# VPAC0_CP_INTD_CFG_INTD_CFG register map
Vendor: Texas Instruments
Peripheral module from a debugger description file (folder J721S2).
Registers are 32-bit, access not given, reset 0x0 unless marked. A register's access mark holds for its fields unless they carry their own. Offsets are as the file gives them; lines under a group give offsets from that group; [hi:lo] are bit positions; {n}, {i} and the like mark numbered series; 'fields as' and 'values as' point back to an identical list; <NAME> marks a mode.

## VPAC0_CP_INTD_CFG_INTD_CFG (part 1 of 2)
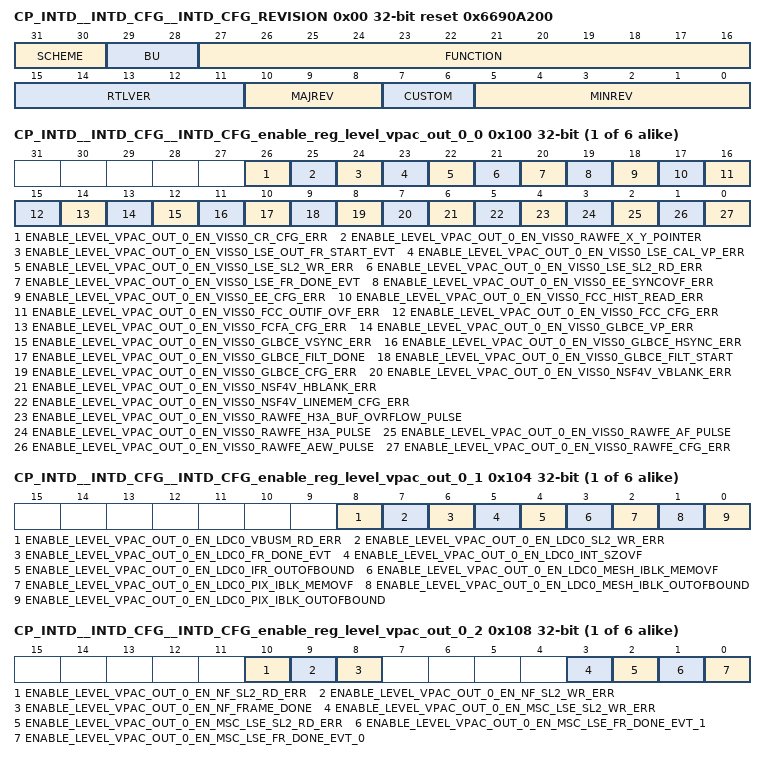
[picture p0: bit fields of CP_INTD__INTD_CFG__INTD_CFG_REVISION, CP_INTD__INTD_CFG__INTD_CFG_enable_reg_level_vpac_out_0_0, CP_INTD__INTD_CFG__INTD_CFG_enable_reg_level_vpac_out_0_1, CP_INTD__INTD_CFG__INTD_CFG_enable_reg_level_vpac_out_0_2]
0x00 CP_INTD__INTD_CFG__INTD_CFG_REVISION ro reset 0x6690A200 — Revision Register
  [31:30] SCHEME
  [29:28] BU
  [27:16] FUNCTION — Module ID
  [15:11] RTLVER — RTL revisions
  [10:8] MAJREV — Major revision
  [7:6] CUSTOM — Custom revision
  [5:0] MINREV — Minor revision
0x10 CP_INTD__INTD_CFG__INTD_CFG_eoi_reg rw — End of Interrupt Register
  [7:0] EOI_VECTOR — End of Interrupt Vector
0x14 CP_INTD__INTD_CFG__INTD_CFG_intr_vector_reg ro — Interrupt Vector Register
  [31:0] INTR_VECTOR
{0x100+0x20*i} CP_INTD__INTD_CFG__INTD_CFG_enable_reg_level_vpac_out_{i}_0 (i=0..5) — Enable Register {8i}
  [26] ENABLE_LEVEL_VPAC_OUT_{i}_EN_VISS0_CR_CFG_ERR — Enable Set for level_vpac_out_{i}_en_viss0_cr_cfg_err (access R/W1TS)
  [25] ENABLE_LEVEL_VPAC_OUT_{i}_EN_VISS0_RAWFE_X_Y_POINTER — Enable Set for level_vpac_out_{i}_en_viss0_rawfe_x_y_pointer (access R/W1TS)
  [24] ENABLE_LEVEL_VPAC_OUT_{i}_EN_VISS0_LSE_OUT_FR_START_EVT — Enable Set for level_vpac_out_{i}_en_viss0_lse_out_fr_start_evt (access R/W1TS)
  [23] ENABLE_LEVEL_VPAC_OUT_{i}_EN_VISS0_LSE_CAL_VP_ERR — Enable Set for level_vpac_out_{i}_en_viss0_lse_cal_vp_err (access R/W1TS)
  [22] ENABLE_LEVEL_VPAC_OUT_{i}_EN_VISS0_LSE_SL2_WR_ERR — Enable Set for level_vpac_out_{i}_en_viss0_lse_sl2_wr_err (access R/W1TS)
  [21] ENABLE_LEVEL_VPAC_OUT_{i}_EN_VISS0_LSE_SL2_RD_ERR — Enable Set for level_vpac_out_{i}_en_viss0_lse_sl2_rd_err (access R/W1TS)
  [20] ENABLE_LEVEL_VPAC_OUT_{i}_EN_VISS0_LSE_FR_DONE_EVT — Enable Set for level_vpac_out_{i}_en_viss0_lse_fr_done_evt (access R/W1TS)
  [19] ENABLE_LEVEL_VPAC_OUT_{i}_EN_VISS0_EE_SYNCOVF_ERR — Enable Set for level_vpac_out_{i}_en_viss0_ee_syncovf_err (access R/W1TS)
  [18] ENABLE_LEVEL_VPAC_OUT_{i}_EN_VISS0_EE_CFG_ERR — Enable Set for level_vpac_out_{i}_en_viss0_ee_cfg_err (access R/W1TS)
  [17] ENABLE_LEVEL_VPAC_OUT_{i}_EN_VISS0_FCC_HIST_READ_ERR — Enable Set for level_vpac_out_{i}_en_viss0_fcc_hist_read_err (access R/W1TS)
  [16] ENABLE_LEVEL_VPAC_OUT_{i}_EN_VISS0_FCC_OUTIF_OVF_ERR — Enable Set for level_vpac_out_{i}_en_viss0_fcc_outif_ovf_err (access R/W1TS)
  [15] ENABLE_LEVEL_VPAC_OUT_{i}_EN_VISS0_FCC_CFG_ERR — Enable Set for level_vpac_out_{i}_en_viss0_fcc_cfg_err (access R/W1TS)
  [14] ENABLE_LEVEL_VPAC_OUT_{i}_EN_VISS0_FCFA_CFG_ERR — Enable Set for level_vpac_out_{i}_en_viss0_fcfa_cfg_err (access R/W1TS)
  [13] ENABLE_LEVEL_VPAC_OUT_{i}_EN_VISS0_GLBCE_VP_ERR — Enable Set for level_vpac_out_{i}_en_viss0_glbce_vp_err (access R/W1TS)
  [12] ENABLE_LEVEL_VPAC_OUT_{i}_EN_VISS0_GLBCE_VSYNC_ERR — Enable Set for level_vpac_out_{i}_en_viss0_glbce_vsync_err (access R/W1TS)
  [11] ENABLE_LEVEL_VPAC_OUT_{i}_EN_VISS0_GLBCE_HSYNC_ERR — Enable Set for level_vpac_out_{i}_en_viss0_glbce_hsync_err (access R/W1TS)
  [10] ENABLE_LEVEL_VPAC_OUT_{i}_EN_VISS0_GLBCE_FILT_DONE — Enable Set for level_vpac_out_{i}_en_viss0_glbce_filt_done (access R/W1TS)
  [9] ENABLE_LEVEL_VPAC_OUT_{i}_EN_VISS0_GLBCE_FILT_START — Enable Set for level_vpac_out_{i}_en_viss0_glbce_filt_start (access R/W1TS)
  [8] ENABLE_LEVEL_VPAC_OUT_{i}_EN_VISS0_GLBCE_CFG_ERR — Enable Set for level_vpac_out_{i}_en_viss0_glbce_cfg_err (access R/W1TS)
  [7] ENABLE_LEVEL_VPAC_OUT_{i}_EN_VISS0_NSF4V_VBLANK_ERR — Enable Set for level_vpac_out_{i}_en_viss0_nsf4v_vblank_err (access R/W1TS)
  [6] ENABLE_LEVEL_VPAC_OUT_{i}_EN_VISS0_NSF4V_HBLANK_ERR — Enable Set for level_vpac_out_{i}_en_viss0_nsf4v_hblank_err (access R/W1TS)
  [5] ENABLE_LEVEL_VPAC_OUT_{i}_EN_VISS0_NSF4V_LINEMEM_CFG_ERR — Enable Set for level_vpac_out_{i}_en_viss0_nsf4v_linemem_cfg_err (access R/W1TS)
  [4] ENABLE_LEVEL_VPAC_OUT_{i}_EN_VISS0_RAWFE_H3A_BUF_OVRFLOW_PULSE — Enable Set for level_vpac_out_{i}_en_viss0_rawfe_h3a_buf_ovrflow_pulse (access R/W1TS)
  [3] ENABLE_LEVEL_VPAC_OUT_{i}_EN_VISS0_RAWFE_H3A_PULSE — Enable Set for level_vpac_out_{i}_en_viss0_rawfe_h3a_pulse (access R/W1TS)
  [2] ENABLE_LEVEL_VPAC_OUT_{i}_EN_VISS0_RAWFE_AF_PULSE — Enable Set for level_vpac_out_{i}_en_viss0_rawfe_af_pulse (access R/W1TS)
  [1] ENABLE_LEVEL_VPAC_OUT_{i}_EN_VISS0_RAWFE_AEW_PULSE — Enable Set for level_vpac_out_{i}_en_viss0_rawfe_aew_pulse (access R/W1TS)
  [0] ENABLE_LEVEL_VPAC_OUT_{i}_EN_VISS0_RAWFE_CFG_ERR — Enable Set for level_vpac_out_{i}_en_viss0_rawfe_cfg_err (access R/W1TS)
{0x104+0x20*i} CP_INTD__INTD_CFG__INTD_CFG_enable_reg_level_vpac_out_{i}_1 (i=0..5) — Enable Register {8i+1}
  [8] ENABLE_LEVEL_VPAC_OUT_{i}_EN_LDC0_VBUSM_RD_ERR — Enable Set for level_vpac_out_{i}_en_ldc0_vbusm_rd_err (access R/W1TS)
  [7] ENABLE_LEVEL_VPAC_OUT_{i}_EN_LDC0_SL2_WR_ERR — Enable Set for level_vpac_out_{i}_en_ldc0_sl2_wr_err (access R/W1TS)
  [6] ENABLE_LEVEL_VPAC_OUT_{i}_EN_LDC0_FR_DONE_EVT — Enable Set for level_vpac_out_{i}_en_ldc0_fr_done_evt (access R/W1TS)
  [5] ENABLE_LEVEL_VPAC_OUT_{i}_EN_LDC0_INT_SZOVF — Enable Set for level_vpac_out_{i}_en_ldc0_int_szovf (access R/W1TS)
  [4] ENABLE_LEVEL_VPAC_OUT_{i}_EN_LDC0_IFR_OUTOFBOUND — Enable Set for level_vpac_out_{i}_en_ldc0_ifr_outofbound (access R/W1TS)
  [3] ENABLE_LEVEL_VPAC_OUT_{i}_EN_LDC0_MESH_IBLK_MEMOVF — Enable Set for level_vpac_out_{i}_en_ldc0_mesh_iblk_memovf (access R/W1TS)
  [2] ENABLE_LEVEL_VPAC_OUT_{i}_EN_LDC0_PIX_IBLK_MEMOVF — Enable Set for level_vpac_out_{i}_en_ldc0_pix_iblk_memovf (access R/W1TS)
  [1] ENABLE_LEVEL_VPAC_OUT_{i}_EN_LDC0_MESH_IBLK_OUTOFBOUND — Enable Set for level_vpac_out_{i}_en_ldc0_mesh_iblk_outofbound (access R/W1TS)
  [0] ENABLE_LEVEL_VPAC_OUT_{i}_EN_LDC0_PIX_IBLK_OUTOFBOUND — Enable Set for level_vpac_out_{i}_en_ldc0_pix_iblk_outofbound (access R/W1TS)
{0x108+0x20*i} CP_INTD__INTD_CFG__INTD_CFG_enable_reg_level_vpac_out_{i}_2 (i=0..5) — Enable Register {8i+2}
  [10] ENABLE_LEVEL_VPAC_OUT_{i}_EN_NF_SL2_RD_ERR — Enable Set for level_vpac_out_{i}_en_nf_sl2_rd_err (access R/W1TS)
  [9] ENABLE_LEVEL_VPAC_OUT_{i}_EN_NF_SL2_WR_ERR — Enable Set for level_vpac_out_{i}_en_nf_sl2_wr_err (access R/W1TS)
  [8] ENABLE_LEVEL_VPAC_OUT_{i}_EN_NF_FRAME_DONE — Enable Set for level_vpac_out_{i}_en_nf_frame_done (access R/W1TS)
  [3] ENABLE_LEVEL_VPAC_OUT_{i}_EN_MSC_LSE_SL2_WR_ERR — Enable Set for level_vpac_out_{i}_en_msc_lse_sl2_wr_err (access R/W1TS)
  [2] ENABLE_LEVEL_VPAC_OUT_{i}_EN_MSC_LSE_SL2_RD_ERR — Enable Set for level_vpac_out_{i}_en_msc_lse_sl2_rd_err (access R/W1TS)
  [1] ENABLE_LEVEL_VPAC_OUT_{i}_EN_MSC_LSE_FR_DONE_EVT_1 — Enable Set for level_vpac_out_{i}_en_msc_lse_fr_done_evt_1 (access R/W1TS)
  [0] ENABLE_LEVEL_VPAC_OUT_{i}_EN_MSC_LSE_FR_DONE_EVT_0 — Enable Set for level_vpac_out_{i}_en_msc_lse_fr_done_evt_0 (access R/W1TS)
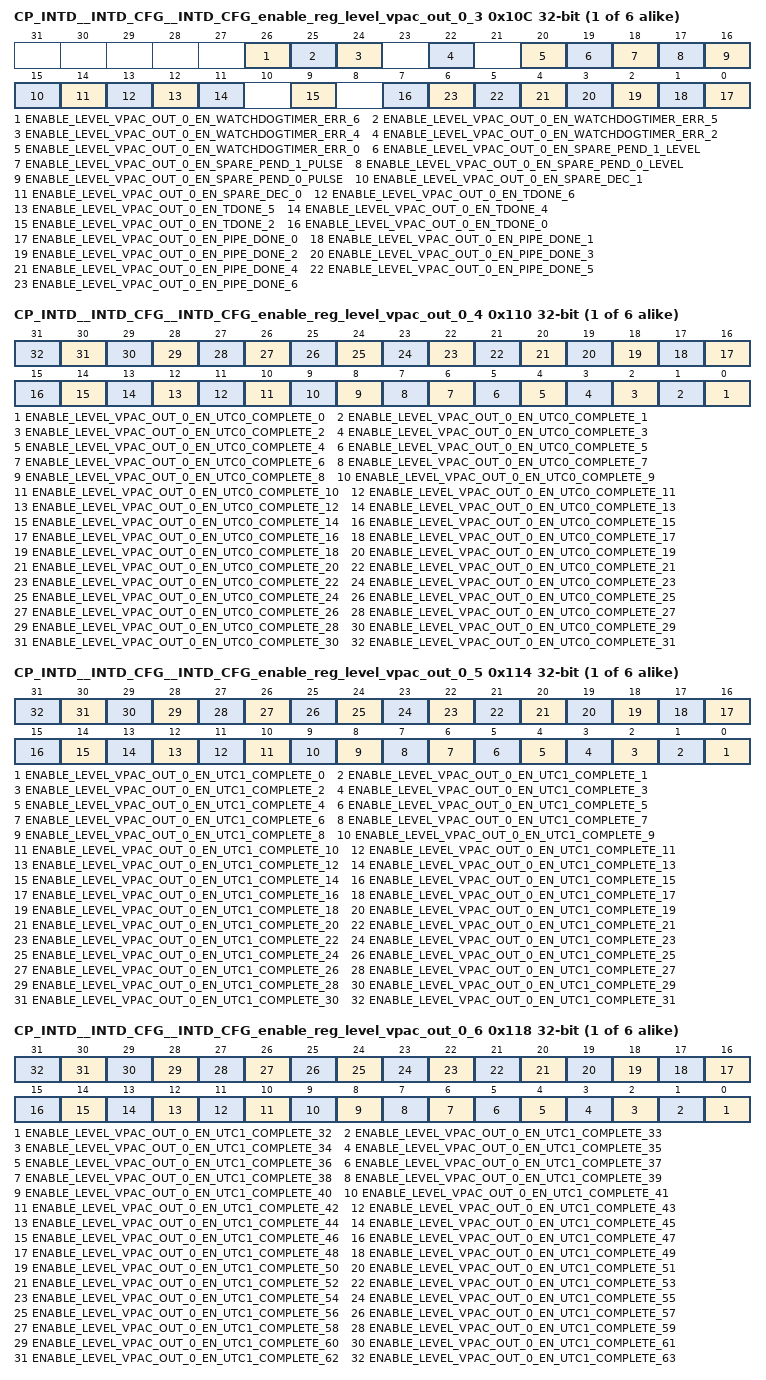
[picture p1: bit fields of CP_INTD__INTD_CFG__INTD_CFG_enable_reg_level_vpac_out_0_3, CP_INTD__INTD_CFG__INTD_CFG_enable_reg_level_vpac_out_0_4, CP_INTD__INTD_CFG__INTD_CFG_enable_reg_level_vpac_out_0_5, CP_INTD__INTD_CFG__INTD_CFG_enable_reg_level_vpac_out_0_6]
{0x10C+0x20*i} CP_INTD__INTD_CFG__INTD_CFG_enable_reg_level_vpac_out_{i}_3 (i=0..5) — Enable Register {8i+3}
  [26] ENABLE_LEVEL_VPAC_OUT_{i}_EN_WATCHDOGTIMER_ERR_6 — Enable Set for level_vpac_out_{i}_en_watchdogtimer_err_6 (access R/W1TS)
  [25] ENABLE_LEVEL_VPAC_OUT_{i}_EN_WATCHDOGTIMER_ERR_5 — Enable Set for level_vpac_out_{i}_en_watchdogtimer_err_5 (access R/W1TS)
  [24] ENABLE_LEVEL_VPAC_OUT_{i}_EN_WATCHDOGTIMER_ERR_4 — Enable Set for level_vpac_out_{i}_en_watchdogtimer_err_4 (access R/W1TS)
  [22] ENABLE_LEVEL_VPAC_OUT_{i}_EN_WATCHDOGTIMER_ERR_2 — Enable Set for level_vpac_out_{i}_en_watchdogtimer_err_2 (access R/W1TS)
  [20] ENABLE_LEVEL_VPAC_OUT_{i}_EN_WATCHDOGTIMER_ERR_0 — Enable Set for level_vpac_out_{i}_en_watchdogtimer_err_0 (access R/W1TS)
  [19] ENABLE_LEVEL_VPAC_OUT_{i}_EN_SPARE_PEND_1_LEVEL — Enable Set for level_vpac_out_{i}_en_spare_pend_1_level (access R/W1TS)
  [18] ENABLE_LEVEL_VPAC_OUT_{i}_EN_SPARE_PEND_1_PULSE — Enable Set for level_vpac_out_{i}_en_spare_pend_1_pulse (access R/W1TS)
  [17] ENABLE_LEVEL_VPAC_OUT_{i}_EN_SPARE_PEND_0_LEVEL — Enable Set for level_vpac_out_{i}_en_spare_pend_0_level (access R/W1TS)
  [16] ENABLE_LEVEL_VPAC_OUT_{i}_EN_SPARE_PEND_0_PULSE — Enable Set for level_vpac_out_{i}_en_spare_pend_0_pulse (access R/W1TS)
  [15] ENABLE_LEVEL_VPAC_OUT_{i}_EN_SPARE_DEC_1 — Enable Set for level_vpac_out_{i}_en_spare_dec_1 (access R/W1TS)
  [14] ENABLE_LEVEL_VPAC_OUT_{i}_EN_SPARE_DEC_0 — Enable Set for level_vpac_out_{i}_en_spare_dec_0 (access R/W1TS)
  [13] ENABLE_LEVEL_VPAC_OUT_{i}_EN_TDONE_6 — Enable Set for level_vpac_out_{i}_en_tdone_6 (access R/W1TS)
  [12] ENABLE_LEVEL_VPAC_OUT_{i}_EN_TDONE_5 — Enable Set for level_vpac_out_{i}_en_tdone_5 (access R/W1TS)
  [11] ENABLE_LEVEL_VPAC_OUT_{i}_EN_TDONE_4 — Enable Set for level_vpac_out_{i}_en_tdone_4 (access R/W1TS)
  [9] ENABLE_LEVEL_VPAC_OUT_{i}_EN_TDONE_2 — Enable Set for level_vpac_out_{i}_en_tdone_2 (access R/W1TS)
  [7] ENABLE_LEVEL_VPAC_OUT_{i}_EN_TDONE_0 — Enable Set for level_vpac_out_{i}_en_tdone_0 (access R/W1TS)
  [n] ENABLE_LEVEL_VPAC_OUT_{i}_EN_PIPE_DONE_{n} (n=0..6) — Enable Set for level_vpac_out_{i}_en_pipe_done_{n} (access R/W1TS)
{0x110+0x20*i} CP_INTD__INTD_CFG__INTD_CFG_enable_reg_level_vpac_out_{i}_4 (i=0..5) — Enable Register {8i+4}
  [n] ENABLE_LEVEL_VPAC_OUT_{i}_EN_UTC0_COMPLETE_{n} (n=0..31) — Enable Set for level_vpac_out_{i}_en_utc0_complete_{n} (access R/W1TS)
{0x114+0x20*i} CP_INTD__INTD_CFG__INTD_CFG_enable_reg_level_vpac_out_{i}_5 (i=0..5) — Enable Register {8i+5}
  [n] ENABLE_LEVEL_VPAC_OUT_{i}_EN_UTC1_COMPLETE_{n} (n=0..31) — Enable Set for level_vpac_out_{i}_en_utc1_complete_{n} (access R/W1TS)
{0x118+0x20*i} CP_INTD__INTD_CFG__INTD_CFG_enable_reg_level_vpac_out_{i}_6 (i=0..5) — Enable Register {8i+6}
  [n-32] ENABLE_LEVEL_VPAC_OUT_{i}_EN_UTC1_COMPLETE_{n} (n=32..63) — Enable Set for level_vpac_out_{i}_en_utc1_complete_{n} (access R/W1TS)
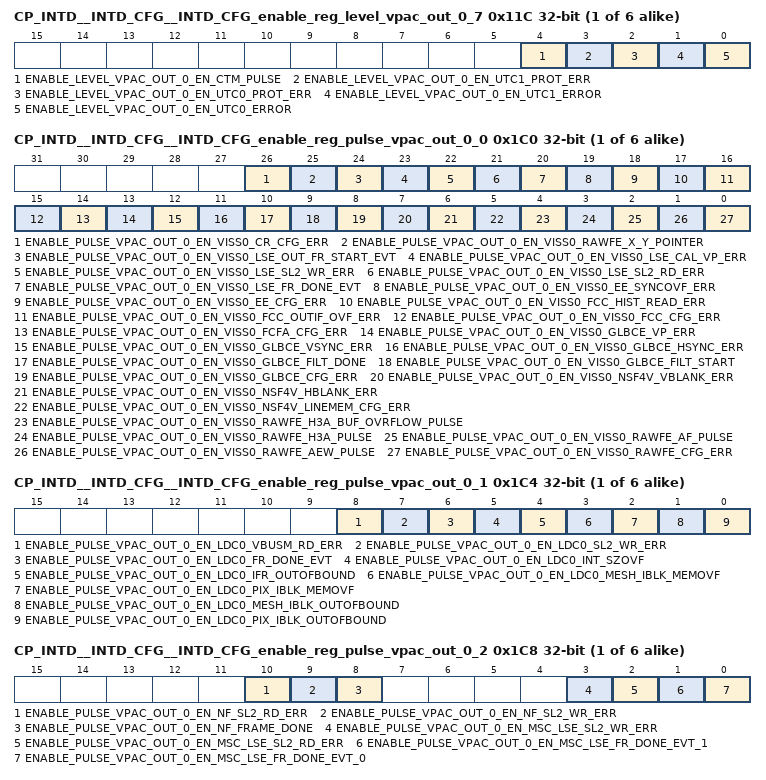
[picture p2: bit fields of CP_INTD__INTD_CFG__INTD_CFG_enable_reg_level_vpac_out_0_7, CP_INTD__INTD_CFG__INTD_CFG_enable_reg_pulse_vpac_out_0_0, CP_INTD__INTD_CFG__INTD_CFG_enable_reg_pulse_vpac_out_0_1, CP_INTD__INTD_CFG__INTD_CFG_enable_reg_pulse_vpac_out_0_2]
{0x11C+0x20*i} CP_INTD__INTD_CFG__INTD_CFG_enable_reg_level_vpac_out_{i}_7 (i=0..5) — Enable Register {8i+7}
  [4] ENABLE_LEVEL_VPAC_OUT_{i}_EN_CTM_PULSE — Enable Set for level_vpac_out_{i}_en_ctm_pulse (access R/W1TS)
  [3] ENABLE_LEVEL_VPAC_OUT_{i}_EN_UTC1_PROT_ERR — Enable Set for level_vpac_out_{i}_en_utc1_prot_err (access R/W1TS)
  [2] ENABLE_LEVEL_VPAC_OUT_{i}_EN_UTC0_PROT_ERR — Enable Set for level_vpac_out_{i}_en_utc0_prot_err (access R/W1TS)
  [1] ENABLE_LEVEL_VPAC_OUT_{i}_EN_UTC1_ERROR — Enable Set for level_vpac_out_{i}_en_utc1_error (access R/W1TS)
  [0] ENABLE_LEVEL_VPAC_OUT_{i}_EN_UTC0_ERROR — Enable Set for level_vpac_out_{i}_en_utc0_error (access R/W1TS)
{0x1C0+0x20*i} CP_INTD__INTD_CFG__INTD_CFG_enable_reg_pulse_vpac_out_{i}_0 (i=0..5) — Enable Register {8i+48}
  [26] ENABLE_PULSE_VPAC_OUT_{i}_EN_VISS0_CR_CFG_ERR — Enable Set for pulse_vpac_out_{i}_en_viss0_cr_cfg_err (access R/W1TS)
  [25] ENABLE_PULSE_VPAC_OUT_{i}_EN_VISS0_RAWFE_X_Y_POINTER — Enable Set for pulse_vpac_out_{i}_en_viss0_rawfe_x_y_pointer (access R/W1TS)
  [24] ENABLE_PULSE_VPAC_OUT_{i}_EN_VISS0_LSE_OUT_FR_START_EVT — Enable Set for pulse_vpac_out_{i}_en_viss0_lse_out_fr_start_evt (access R/W1TS)
  [23] ENABLE_PULSE_VPAC_OUT_{i}_EN_VISS0_LSE_CAL_VP_ERR — Enable Set for pulse_vpac_out_{i}_en_viss0_lse_cal_vp_err (access R/W1TS)
  [22] ENABLE_PULSE_VPAC_OUT_{i}_EN_VISS0_LSE_SL2_WR_ERR — Enable Set for pulse_vpac_out_{i}_en_viss0_lse_sl2_wr_err (access R/W1TS)
  [21] ENABLE_PULSE_VPAC_OUT_{i}_EN_VISS0_LSE_SL2_RD_ERR — Enable Set for pulse_vpac_out_{i}_en_viss0_lse_sl2_rd_err (access R/W1TS)
  [20] ENABLE_PULSE_VPAC_OUT_{i}_EN_VISS0_LSE_FR_DONE_EVT — Enable Set for pulse_vpac_out_{i}_en_viss0_lse_fr_done_evt (access R/W1TS)
  [19] ENABLE_PULSE_VPAC_OUT_{i}_EN_VISS0_EE_SYNCOVF_ERR — Enable Set for pulse_vpac_out_{i}_en_viss0_ee_syncovf_err (access R/W1TS)
  [18] ENABLE_PULSE_VPAC_OUT_{i}_EN_VISS0_EE_CFG_ERR — Enable Set for pulse_vpac_out_{i}_en_viss0_ee_cfg_err (access R/W1TS)
  [17] ENABLE_PULSE_VPAC_OUT_{i}_EN_VISS0_FCC_HIST_READ_ERR — Enable Set for pulse_vpac_out_{i}_en_viss0_fcc_hist_read_err (access R/W1TS)
  [16] ENABLE_PULSE_VPAC_OUT_{i}_EN_VISS0_FCC_OUTIF_OVF_ERR — Enable Set for pulse_vpac_out_{i}_en_viss0_fcc_outif_ovf_err (access R/W1TS)
  [15] ENABLE_PULSE_VPAC_OUT_{i}_EN_VISS0_FCC_CFG_ERR — Enable Set for pulse_vpac_out_{i}_en_viss0_fcc_cfg_err (access R/W1TS)
  [14] ENABLE_PULSE_VPAC_OUT_{i}_EN_VISS0_FCFA_CFG_ERR — Enable Set for pulse_vpac_out_{i}_en_viss0_fcfa_cfg_err (access R/W1TS)
  [13] ENABLE_PULSE_VPAC_OUT_{i}_EN_VISS0_GLBCE_VP_ERR — Enable Set for pulse_vpac_out_{i}_en_viss0_glbce_vp_err (access R/W1TS)
  [12] ENABLE_PULSE_VPAC_OUT_{i}_EN_VISS0_GLBCE_VSYNC_ERR — Enable Set for pulse_vpac_out_{i}_en_viss0_glbce_vsync_err (access R/W1TS)
  [11] ENABLE_PULSE_VPAC_OUT_{i}_EN_VISS0_GLBCE_HSYNC_ERR — Enable Set for pulse_vpac_out_{i}_en_viss0_glbce_hsync_err (access R/W1TS)
  [10] ENABLE_PULSE_VPAC_OUT_{i}_EN_VISS0_GLBCE_FILT_DONE — Enable Set for pulse_vpac_out_{i}_en_viss0_glbce_filt_done (access R/W1TS)
  [9] ENABLE_PULSE_VPAC_OUT_{i}_EN_VISS0_GLBCE_FILT_START — Enable Set for pulse_vpac_out_{i}_en_viss0_glbce_filt_start (access R/W1TS)
  [8] ENABLE_PULSE_VPAC_OUT_{i}_EN_VISS0_GLBCE_CFG_ERR — Enable Set for pulse_vpac_out_{i}_en_viss0_glbce_cfg_err (access R/W1TS)
  [7] ENABLE_PULSE_VPAC_OUT_{i}_EN_VISS0_NSF4V_VBLANK_ERR — Enable Set for pulse_vpac_out_{i}_en_viss0_nsf4v_vblank_err (access R/W1TS)
  [6] ENABLE_PULSE_VPAC_OUT_{i}_EN_VISS0_NSF4V_HBLANK_ERR — Enable Set for pulse_vpac_out_{i}_en_viss0_nsf4v_hblank_err (access R/W1TS)
  [5] ENABLE_PULSE_VPAC_OUT_{i}_EN_VISS0_NSF4V_LINEMEM_CFG_ERR — Enable Set for pulse_vpac_out_{i}_en_viss0_nsf4v_linemem_cfg_err (access R/W1TS)
  [4] ENABLE_PULSE_VPAC_OUT_{i}_EN_VISS0_RAWFE_H3A_BUF_OVRFLOW_PULSE — Enable Set for pulse_vpac_out_{i}_en_viss0_rawfe_h3a_buf_ovrflow_pulse (access R/W1TS)
  [3] ENABLE_PULSE_VPAC_OUT_{i}_EN_VISS0_RAWFE_H3A_PULSE — Enable Set for pulse_vpac_out_{i}_en_viss0_rawfe_h3a_pulse (access R/W1TS)
  [2] ENABLE_PULSE_VPAC_OUT_{i}_EN_VISS0_RAWFE_AF_PULSE — Enable Set for pulse_vpac_out_{i}_en_viss0_rawfe_af_pulse (access R/W1TS)
  [1] ENABLE_PULSE_VPAC_OUT_{i}_EN_VISS0_RAWFE_AEW_PULSE — Enable Set for pulse_vpac_out_{i}_en_viss0_rawfe_aew_pulse (access R/W1TS)
  [0] ENABLE_PULSE_VPAC_OUT_{i}_EN_VISS0_RAWFE_CFG_ERR — Enable Set for pulse_vpac_out_{i}_en_viss0_rawfe_cfg_err (access R/W1TS)
{0x1C4+0x20*i} CP_INTD__INTD_CFG__INTD_CFG_enable_reg_pulse_vpac_out_{i}_1 (i=0..5) — Enable Register {8i+49}
  [8] ENABLE_PULSE_VPAC_OUT_{i}_EN_LDC0_VBUSM_RD_ERR — Enable Set for pulse_vpac_out_{i}_en_ldc0_vbusm_rd_err (access R/W1TS)
  [7] ENABLE_PULSE_VPAC_OUT_{i}_EN_LDC0_SL2_WR_ERR — Enable Set for pulse_vpac_out_{i}_en_ldc0_sl2_wr_err (access R/W1TS)
  [6] ENABLE_PULSE_VPAC_OUT_{i}_EN_LDC0_FR_DONE_EVT — Enable Set for pulse_vpac_out_{i}_en_ldc0_fr_done_evt (access R/W1TS)
  [5] ENABLE_PULSE_VPAC_OUT_{i}_EN_LDC0_INT_SZOVF — Enable Set for pulse_vpac_out_{i}_en_ldc0_int_szovf (access R/W1TS)
  [4] ENABLE_PULSE_VPAC_OUT_{i}_EN_LDC0_IFR_OUTOFBOUND — Enable Set for pulse_vpac_out_{i}_en_ldc0_ifr_outofbound (access R/W1TS)
  [3] ENABLE_PULSE_VPAC_OUT_{i}_EN_LDC0_MESH_IBLK_MEMOVF — Enable Set for pulse_vpac_out_{i}_en_ldc0_mesh_iblk_memovf (access R/W1TS)
  [2] ENABLE_PULSE_VPAC_OUT_{i}_EN_LDC0_PIX_IBLK_MEMOVF — Enable Set for pulse_vpac_out_{i}_en_ldc0_pix_iblk_memovf (access R/W1TS)
  [1] ENABLE_PULSE_VPAC_OUT_{i}_EN_LDC0_MESH_IBLK_OUTOFBOUND — Enable Set for pulse_vpac_out_{i}_en_ldc0_mesh_iblk_outofbound (access R/W1TS)
  [0] ENABLE_PULSE_VPAC_OUT_{i}_EN_LDC0_PIX_IBLK_OUTOFBOUND — Enable Set for pulse_vpac_out_{i}_en_ldc0_pix_iblk_outofbound (access R/W1TS)
{0x1C8+0x20*i} CP_INTD__INTD_CFG__INTD_CFG_enable_reg_pulse_vpac_out_{i}_2 (i=0..5) — Enable Register {8i+50}
  [10] ENABLE_PULSE_VPAC_OUT_{i}_EN_NF_SL2_RD_ERR — Enable Set for pulse_vpac_out_{i}_en_nf_sl2_rd_err (access R/W1TS)
  [9] ENABLE_PULSE_VPAC_OUT_{i}_EN_NF_SL2_WR_ERR — Enable Set for pulse_vpac_out_{i}_en_nf_sl2_wr_err (access R/W1TS)
  [8] ENABLE_PULSE_VPAC_OUT_{i}_EN_NF_FRAME_DONE — Enable Set for pulse_vpac_out_{i}_en_nf_frame_done (access R/W1TS)
  [3] ENABLE_PULSE_VPAC_OUT_{i}_EN_MSC_LSE_SL2_WR_ERR — Enable Set for pulse_vpac_out_{i}_en_msc_lse_sl2_wr_err (access R/W1TS)
  [2] ENABLE_PULSE_VPAC_OUT_{i}_EN_MSC_LSE_SL2_RD_ERR — Enable Set for pulse_vpac_out_{i}_en_msc_lse_sl2_rd_err (access R/W1TS)
  [1] ENABLE_PULSE_VPAC_OUT_{i}_EN_MSC_LSE_FR_DONE_EVT_1 — Enable Set for pulse_vpac_out_{i}_en_msc_lse_fr_done_evt_1 (access R/W1TS)
  [0] ENABLE_PULSE_VPAC_OUT_{i}_EN_MSC_LSE_FR_DONE_EVT_0 — Enable Set for pulse_vpac_out_{i}_en_msc_lse_fr_done_evt_0 (access R/W1TS)
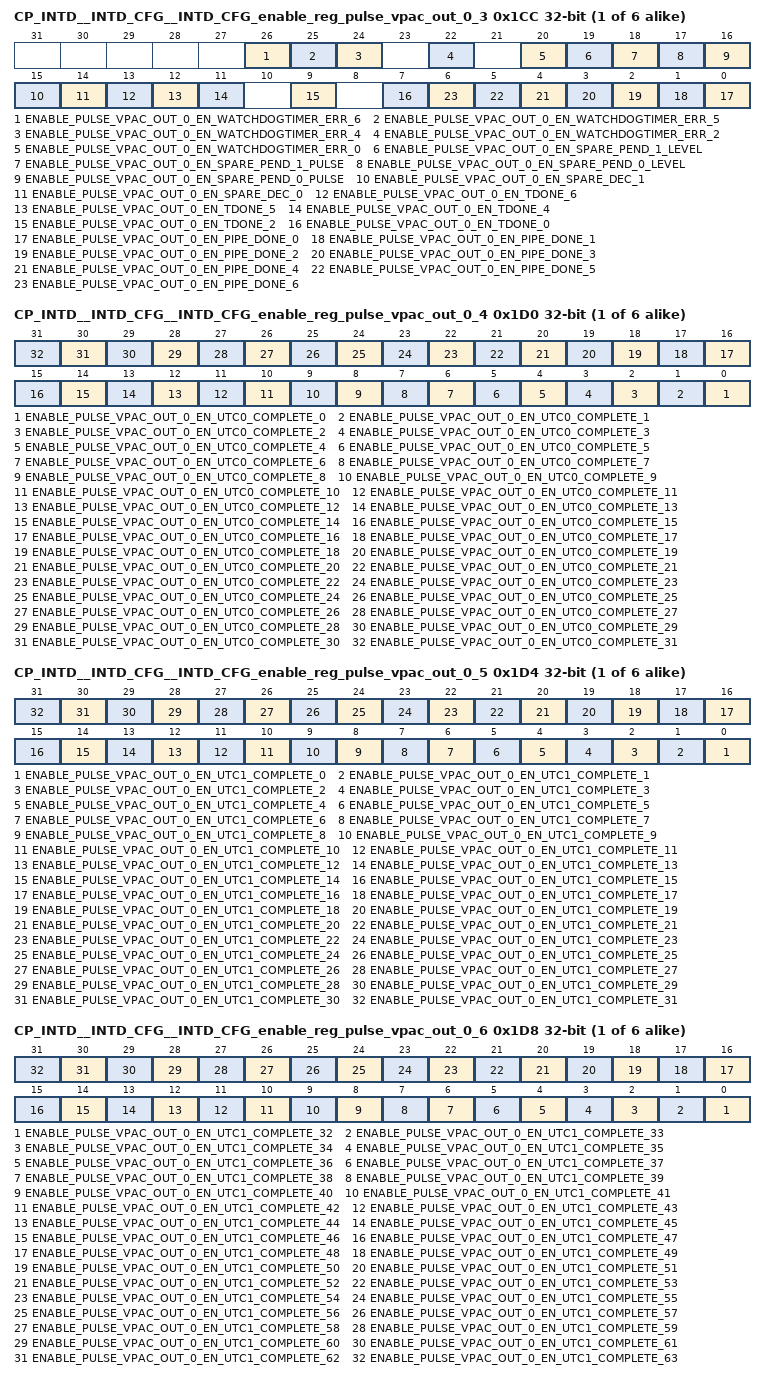
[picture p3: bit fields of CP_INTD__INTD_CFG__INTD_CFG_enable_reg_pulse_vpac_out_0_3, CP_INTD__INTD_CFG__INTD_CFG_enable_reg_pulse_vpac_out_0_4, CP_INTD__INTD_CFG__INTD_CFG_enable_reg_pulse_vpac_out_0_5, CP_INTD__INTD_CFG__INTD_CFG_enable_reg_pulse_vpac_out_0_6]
{0x1CC+0x20*i} CP_INTD__INTD_CFG__INTD_CFG_enable_reg_pulse_vpac_out_{i}_3 (i=0..5) — Enable Register {8i+51}
  [26] ENABLE_PULSE_VPAC_OUT_{i}_EN_WATCHDOGTIMER_ERR_6 — Enable Set for pulse_vpac_out_{i}_en_watchdogtimer_err_6 (access R/W1TS)
  [25] ENABLE_PULSE_VPAC_OUT_{i}_EN_WATCHDOGTIMER_ERR_5 — Enable Set for pulse_vpac_out_{i}_en_watchdogtimer_err_5 (access R/W1TS)
  [24] ENABLE_PULSE_VPAC_OUT_{i}_EN_WATCHDOGTIMER_ERR_4 — Enable Set for pulse_vpac_out_{i}_en_watchdogtimer_err_4 (access R/W1TS)
  [22] ENABLE_PULSE_VPAC_OUT_{i}_EN_WATCHDOGTIMER_ERR_2 — Enable Set for pulse_vpac_out_{i}_en_watchdogtimer_err_2 (access R/W1TS)
  [20] ENABLE_PULSE_VPAC_OUT_{i}_EN_WATCHDOGTIMER_ERR_0 — Enable Set for pulse_vpac_out_{i}_en_watchdogtimer_err_0 (access R/W1TS)
  [19] ENABLE_PULSE_VPAC_OUT_{i}_EN_SPARE_PEND_1_LEVEL — Enable Set for pulse_vpac_out_{i}_en_spare_pend_1_level (access R/W1TS)
  [18] ENABLE_PULSE_VPAC_OUT_{i}_EN_SPARE_PEND_1_PULSE — Enable Set for pulse_vpac_out_{i}_en_spare_pend_1_pulse (access R/W1TS)
  [17] ENABLE_PULSE_VPAC_OUT_{i}_EN_SPARE_PEND_0_LEVEL — Enable Set for pulse_vpac_out_{i}_en_spare_pend_0_level (access R/W1TS)
  [16] ENABLE_PULSE_VPAC_OUT_{i}_EN_SPARE_PEND_0_PULSE — Enable Set for pulse_vpac_out_{i}_en_spare_pend_0_pulse (access R/W1TS)
  [15] ENABLE_PULSE_VPAC_OUT_{i}_EN_SPARE_DEC_1 — Enable Set for pulse_vpac_out_{i}_en_spare_dec_1 (access R/W1TS)
  [14] ENABLE_PULSE_VPAC_OUT_{i}_EN_SPARE_DEC_0 — Enable Set for pulse_vpac_out_{i}_en_spare_dec_0 (access R/W1TS)
  [13] ENABLE_PULSE_VPAC_OUT_{i}_EN_TDONE_6 — Enable Set for pulse_vpac_out_{i}_en_tdone_6 (access R/W1TS)
  [12] ENABLE_PULSE_VPAC_OUT_{i}_EN_TDONE_5 — Enable Set for pulse_vpac_out_{i}_en_tdone_5 (access R/W1TS)
  [11] ENABLE_PULSE_VPAC_OUT_{i}_EN_TDONE_4 — Enable Set for pulse_vpac_out_{i}_en_tdone_4 (access R/W1TS)
  [9] ENABLE_PULSE_VPAC_OUT_{i}_EN_TDONE_2 — Enable Set for pulse_vpac_out_{i}_en_tdone_2 (access R/W1TS)
  [7] ENABLE_PULSE_VPAC_OUT_{i}_EN_TDONE_0 — Enable Set for pulse_vpac_out_{i}_en_tdone_0 (access R/W1TS)
  [n] ENABLE_PULSE_VPAC_OUT_{i}_EN_PIPE_DONE_{n} (n=0..6) — Enable Set for pulse_vpac_out_{i}_en_pipe_done_{n} (access R/W1TS)
{0x1D0+0x20*i} CP_INTD__INTD_CFG__INTD_CFG_enable_reg_pulse_vpac_out_{i}_4 (i=0..5) — Enable Register {8i+52}
  [n] ENABLE_PULSE_VPAC_OUT_{i}_EN_UTC0_COMPLETE_{n} (n=0..31) — Enable Set for pulse_vpac_out_{i}_en_utc0_complete_{n} (access R/W1TS)
{0x1D4+0x20*i} CP_INTD__INTD_CFG__INTD_CFG_enable_reg_pulse_vpac_out_{i}_5 (i=0..5) — Enable Register {8i+53}
  [n] ENABLE_PULSE_VPAC_OUT_{i}_EN_UTC1_COMPLETE_{n} (n=0..31) — Enable Set for pulse_vpac_out_{i}_en_utc1_complete_{n} (access R/W1TS)
{0x1D8+0x20*i} CP_INTD__INTD_CFG__INTD_CFG_enable_reg_pulse_vpac_out_{i}_6 (i=0..5) — Enable Register {8i+54}
  [n-32] ENABLE_PULSE_VPAC_OUT_{i}_EN_UTC1_COMPLETE_{n} (n=32..63) — Enable Set for pulse_vpac_out_{i}_en_utc1_complete_{n} (access R/W1TS)
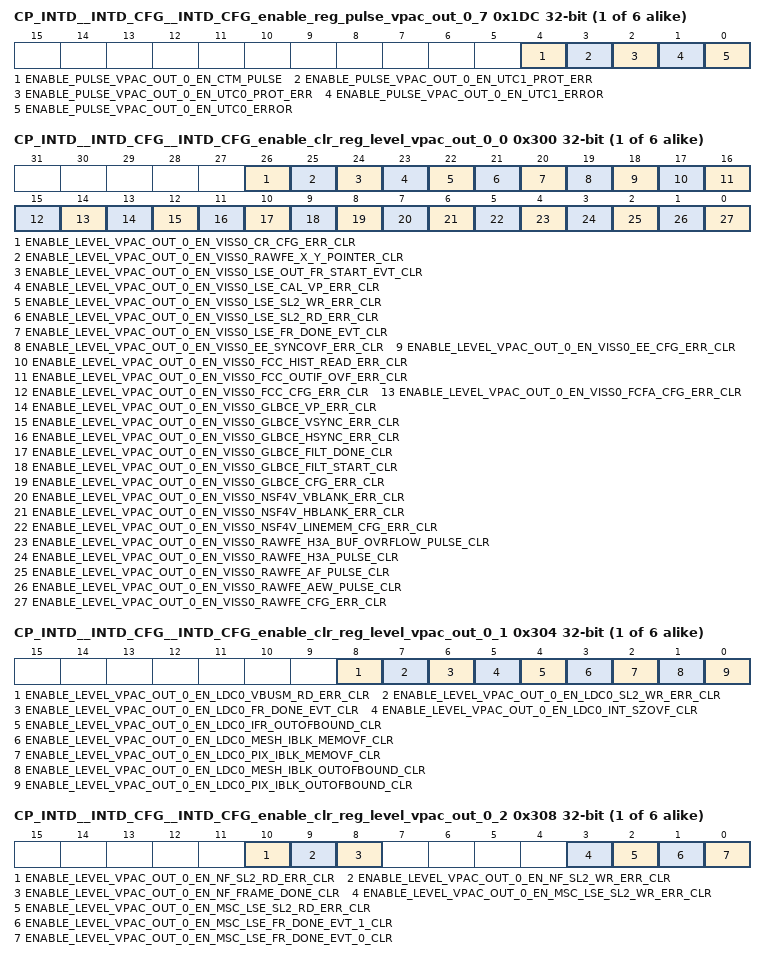
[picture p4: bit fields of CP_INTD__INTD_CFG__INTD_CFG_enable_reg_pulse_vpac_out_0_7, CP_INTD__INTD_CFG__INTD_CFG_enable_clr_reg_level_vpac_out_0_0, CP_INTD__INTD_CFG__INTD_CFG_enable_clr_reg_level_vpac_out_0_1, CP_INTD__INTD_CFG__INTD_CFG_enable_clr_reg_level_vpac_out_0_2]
{0x1DC+0x20*i} CP_INTD__INTD_CFG__INTD_CFG_enable_reg_pulse_vpac_out_{i}_7 (i=0..5) — Enable Register {8i+55}
  [4] ENABLE_PULSE_VPAC_OUT_{i}_EN_CTM_PULSE — Enable Set for pulse_vpac_out_{i}_en_ctm_pulse (access R/W1TS)
  [3] ENABLE_PULSE_VPAC_OUT_{i}_EN_UTC1_PROT_ERR — Enable Set for pulse_vpac_out_{i}_en_utc1_prot_err (access R/W1TS)
  [2] ENABLE_PULSE_VPAC_OUT_{i}_EN_UTC0_PROT_ERR — Enable Set for pulse_vpac_out_{i}_en_utc0_prot_err (access R/W1TS)
  [1] ENABLE_PULSE_VPAC_OUT_{i}_EN_UTC1_ERROR — Enable Set for pulse_vpac_out_{i}_en_utc1_error (access R/W1TS)
  [0] ENABLE_PULSE_VPAC_OUT_{i}_EN_UTC0_ERROR — Enable Set for pulse_vpac_out_{i}_en_utc0_error (access R/W1TS)
{0x300+0x20*i} CP_INTD__INTD_CFG__INTD_CFG_enable_clr_reg_level_vpac_out_{i}_0 (i=0..5) — Enable Clear Register {8i}
  [26] ENABLE_LEVEL_VPAC_OUT_{i}_EN_VISS0_CR_CFG_ERR_CLR — Enable Clear for level_vpac_out_{i}_en_viss0_cr_cfg_err (access R/W1TC)
  [25] ENABLE_LEVEL_VPAC_OUT_{i}_EN_VISS0_RAWFE_X_Y_POINTER_CLR — Enable Clear for level_vpac_out_{i}_en_viss0_rawfe_x_y_pointer (access R/W1TC)
  [24] ENABLE_LEVEL_VPAC_OUT_{i}_EN_VISS0_LSE_OUT_FR_START_EVT_CLR — Enable Clear for level_vpac_out_{i}_en_viss0_lse_out_fr_start_evt (access R/W1TC)
  [23] ENABLE_LEVEL_VPAC_OUT_{i}_EN_VISS0_LSE_CAL_VP_ERR_CLR — Enable Clear for level_vpac_out_{i}_en_viss0_lse_cal_vp_err (access R/W1TC)
  [22] ENABLE_LEVEL_VPAC_OUT_{i}_EN_VISS0_LSE_SL2_WR_ERR_CLR — Enable Clear for level_vpac_out_{i}_en_viss0_lse_sl2_wr_err (access R/W1TC)
  [21] ENABLE_LEVEL_VPAC_OUT_{i}_EN_VISS0_LSE_SL2_RD_ERR_CLR — Enable Clear for level_vpac_out_{i}_en_viss0_lse_sl2_rd_err (access R/W1TC)
  [20] ENABLE_LEVEL_VPAC_OUT_{i}_EN_VISS0_LSE_FR_DONE_EVT_CLR — Enable Clear for level_vpac_out_{i}_en_viss0_lse_fr_done_evt (access R/W1TC)
  [19] ENABLE_LEVEL_VPAC_OUT_{i}_EN_VISS0_EE_SYNCOVF_ERR_CLR — Enable Clear for level_vpac_out_{i}_en_viss0_ee_syncovf_err (access R/W1TC)
  [18] ENABLE_LEVEL_VPAC_OUT_{i}_EN_VISS0_EE_CFG_ERR_CLR — Enable Clear for level_vpac_out_{i}_en_viss0_ee_cfg_err (access R/W1TC)
  [17] ENABLE_LEVEL_VPAC_OUT_{i}_EN_VISS0_FCC_HIST_READ_ERR_CLR — Enable Clear for level_vpac_out_{i}_en_viss0_fcc_hist_read_err (access R/W1TC)
  [16] ENABLE_LEVEL_VPAC_OUT_{i}_EN_VISS0_FCC_OUTIF_OVF_ERR_CLR — Enable Clear for level_vpac_out_{i}_en_viss0_fcc_outif_ovf_err (access R/W1TC)
  [15] ENABLE_LEVEL_VPAC_OUT_{i}_EN_VISS0_FCC_CFG_ERR_CLR — Enable Clear for level_vpac_out_{i}_en_viss0_fcc_cfg_err (access R/W1TC)
  [14] ENABLE_LEVEL_VPAC_OUT_{i}_EN_VISS0_FCFA_CFG_ERR_CLR — Enable Clear for level_vpac_out_{i}_en_viss0_fcfa_cfg_err (access R/W1TC)
  [13] ENABLE_LEVEL_VPAC_OUT_{i}_EN_VISS0_GLBCE_VP_ERR_CLR — Enable Clear for level_vpac_out_{i}_en_viss0_glbce_vp_err (access R/W1TC)
  [12] ENABLE_LEVEL_VPAC_OUT_{i}_EN_VISS0_GLBCE_VSYNC_ERR_CLR — Enable Clear for level_vpac_out_{i}_en_viss0_glbce_vsync_err (access R/W1TC)
  [11] ENABLE_LEVEL_VPAC_OUT_{i}_EN_VISS0_GLBCE_HSYNC_ERR_CLR — Enable Clear for level_vpac_out_{i}_en_viss0_glbce_hsync_err (access R/W1TC)
  [10] ENABLE_LEVEL_VPAC_OUT_{i}_EN_VISS0_GLBCE_FILT_DONE_CLR — Enable Clear for level_vpac_out_{i}_en_viss0_glbce_filt_done (access R/W1TC)
  [9] ENABLE_LEVEL_VPAC_OUT_{i}_EN_VISS0_GLBCE_FILT_START_CLR — Enable Clear for level_vpac_out_{i}_en_viss0_glbce_filt_start (access R/W1TC)
  [8] ENABLE_LEVEL_VPAC_OUT_{i}_EN_VISS0_GLBCE_CFG_ERR_CLR — Enable Clear for level_vpac_out_{i}_en_viss0_glbce_cfg_err (access R/W1TC)
  [7] ENABLE_LEVEL_VPAC_OUT_{i}_EN_VISS0_NSF4V_VBLANK_ERR_CLR — Enable Clear for level_vpac_out_{i}_en_viss0_nsf4v_vblank_err (access R/W1TC)
  [6] ENABLE_LEVEL_VPAC_OUT_{i}_EN_VISS0_NSF4V_HBLANK_ERR_CLR — Enable Clear for level_vpac_out_{i}_en_viss0_nsf4v_hblank_err (access R/W1TC)
  [5] ENABLE_LEVEL_VPAC_OUT_{i}_EN_VISS0_NSF4V_LINEMEM_CFG_ERR_CLR — Enable Clear for level_vpac_out_{i}_en_viss0_nsf4v_linemem_cfg_err (access R/W1TC)
  [4] ENABLE_LEVEL_VPAC_OUT_{i}_EN_VISS0_RAWFE_H3A_BUF_OVRFLOW_PULSE_CLR — Enable Clear for level_vpac_out_{i}_en_viss0_rawfe_h3a_buf_ovrflow_pulse (access R/W1TC)
  [3] ENABLE_LEVEL_VPAC_OUT_{i}_EN_VISS0_RAWFE_H3A_PULSE_CLR — Enable Clear for level_vpac_out_{i}_en_viss0_rawfe_h3a_pulse (access R/W1TC)
  [2] ENABLE_LEVEL_VPAC_OUT_{i}_EN_VISS0_RAWFE_AF_PULSE_CLR — Enable Clear for level_vpac_out_{i}_en_viss0_rawfe_af_pulse (access R/W1TC)
  [1] ENABLE_LEVEL_VPAC_OUT_{i}_EN_VISS0_RAWFE_AEW_PULSE_CLR — Enable Clear for level_vpac_out_{i}_en_viss0_rawfe_aew_pulse (access R/W1TC)
  [0] ENABLE_LEVEL_VPAC_OUT_{i}_EN_VISS0_RAWFE_CFG_ERR_CLR — Enable Clear for level_vpac_out_{i}_en_viss0_rawfe_cfg_err (access R/W1TC)
{0x304+0x20*i} CP_INTD__INTD_CFG__INTD_CFG_enable_clr_reg_level_vpac_out_{i}_1 (i=0..5) — Enable Clear Register {8i+1}
  [8] ENABLE_LEVEL_VPAC_OUT_{i}_EN_LDC0_VBUSM_RD_ERR_CLR — Enable Clear for level_vpac_out_{i}_en_ldc0_vbusm_rd_err (access R/W1TC)
  [7] ENABLE_LEVEL_VPAC_OUT_{i}_EN_LDC0_SL2_WR_ERR_CLR — Enable Clear for level_vpac_out_{i}_en_ldc0_sl2_wr_err (access R/W1TC)
  [6] ENABLE_LEVEL_VPAC_OUT_{i}_EN_LDC0_FR_DONE_EVT_CLR — Enable Clear for level_vpac_out_{i}_en_ldc0_fr_done_evt (access R/W1TC)
  [5] ENABLE_LEVEL_VPAC_OUT_{i}_EN_LDC0_INT_SZOVF_CLR — Enable Clear for level_vpac_out_{i}_en_ldc0_int_szovf (access R/W1TC)
  [4] ENABLE_LEVEL_VPAC_OUT_{i}_EN_LDC0_IFR_OUTOFBOUND_CLR — Enable Clear for level_vpac_out_{i}_en_ldc0_ifr_outofbound (access R/W1TC)
  [3] ENABLE_LEVEL_VPAC_OUT_{i}_EN_LDC0_MESH_IBLK_MEMOVF_CLR — Enable Clear for level_vpac_out_{i}_en_ldc0_mesh_iblk_memovf (access R/W1TC)
  [2] ENABLE_LEVEL_VPAC_OUT_{i}_EN_LDC0_PIX_IBLK_MEMOVF_CLR — Enable Clear for level_vpac_out_{i}_en_ldc0_pix_iblk_memovf (access R/W1TC)
  [1] ENABLE_LEVEL_VPAC_OUT_{i}_EN_LDC0_MESH_IBLK_OUTOFBOUND_CLR — Enable Clear for level_vpac_out_{i}_en_ldc0_mesh_iblk_outofbound (access R/W1TC)
  [0] ENABLE_LEVEL_VPAC_OUT_{i}_EN_LDC0_PIX_IBLK_OUTOFBOUND_CLR — Enable Clear for level_vpac_out_{i}_en_ldc0_pix_iblk_outofbound (access R/W1TC)
{0x308+0x20*i} CP_INTD__INTD_CFG__INTD_CFG_enable_clr_reg_level_vpac_out_{i}_2 (i=0..5) — Enable Clear Register {8i+2}
  [10] ENABLE_LEVEL_VPAC_OUT_{i}_EN_NF_SL2_RD_ERR_CLR — Enable Clear for level_vpac_out_{i}_en_nf_sl2_rd_err (access R/W1TC)
  [9] ENABLE_LEVEL_VPAC_OUT_{i}_EN_NF_SL2_WR_ERR_CLR — Enable Clear for level_vpac_out_{i}_en_nf_sl2_wr_err (access R/W1TC)
  [8] ENABLE_LEVEL_VPAC_OUT_{i}_EN_NF_FRAME_DONE_CLR — Enable Clear for level_vpac_out_{i}_en_nf_frame_done (access R/W1TC)
  [3] ENABLE_LEVEL_VPAC_OUT_{i}_EN_MSC_LSE_SL2_WR_ERR_CLR — Enable Clear for level_vpac_out_{i}_en_msc_lse_sl2_wr_err (access R/W1TC)
  [2] ENABLE_LEVEL_VPAC_OUT_{i}_EN_MSC_LSE_SL2_RD_ERR_CLR — Enable Clear for level_vpac_out_{i}_en_msc_lse_sl2_rd_err (access R/W1TC)
  [1] ENABLE_LEVEL_VPAC_OUT_{i}_EN_MSC_LSE_FR_DONE_EVT_1_CLR — Enable Clear for level_vpac_out_{i}_en_msc_lse_fr_done_evt_1 (access R/W1TC)
  [0] ENABLE_LEVEL_VPAC_OUT_{i}_EN_MSC_LSE_FR_DONE_EVT_0_CLR — Enable Clear for level_vpac_out_{i}_en_msc_lse_fr_done_evt_0 (access R/W1TC)
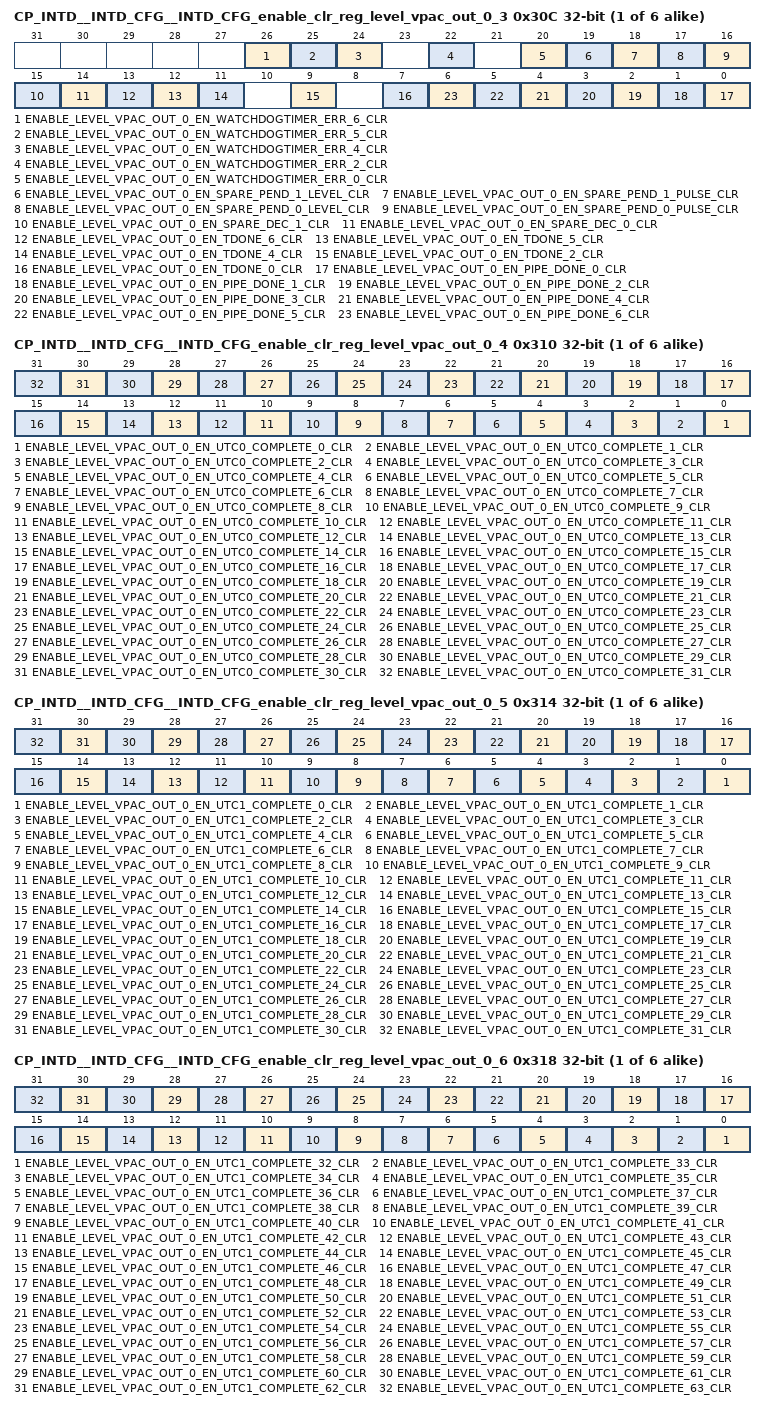
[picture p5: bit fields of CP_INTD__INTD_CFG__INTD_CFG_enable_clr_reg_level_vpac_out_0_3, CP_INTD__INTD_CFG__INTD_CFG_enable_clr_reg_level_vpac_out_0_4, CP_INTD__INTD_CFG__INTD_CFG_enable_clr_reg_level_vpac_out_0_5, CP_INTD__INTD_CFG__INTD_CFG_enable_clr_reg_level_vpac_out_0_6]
{0x30C+0x20*i} CP_INTD__INTD_CFG__INTD_CFG_enable_clr_reg_level_vpac_out_{i}_3 (i=0..5) — Enable Clear Register {8i+3}
  [26] ENABLE_LEVEL_VPAC_OUT_{i}_EN_WATCHDOGTIMER_ERR_6_CLR — Enable Clear for level_vpac_out_{i}_en_watchdogtimer_err_6 (access R/W1TC)
  [25] ENABLE_LEVEL_VPAC_OUT_{i}_EN_WATCHDOGTIMER_ERR_5_CLR — Enable Clear for level_vpac_out_{i}_en_watchdogtimer_err_5 (access R/W1TC)
  [24] ENABLE_LEVEL_VPAC_OUT_{i}_EN_WATCHDOGTIMER_ERR_4_CLR — Enable Clear for level_vpac_out_{i}_en_watchdogtimer_err_4 (access R/W1TC)
  [22] ENABLE_LEVEL_VPAC_OUT_{i}_EN_WATCHDOGTIMER_ERR_2_CLR — Enable Clear for level_vpac_out_{i}_en_watchdogtimer_err_2 (access R/W1TC)
  [20] ENABLE_LEVEL_VPAC_OUT_{i}_EN_WATCHDOGTIMER_ERR_0_CLR — Enable Clear for level_vpac_out_{i}_en_watchdogtimer_err_0 (access R/W1TC)
  [19] ENABLE_LEVEL_VPAC_OUT_{i}_EN_SPARE_PEND_1_LEVEL_CLR — Enable Clear for level_vpac_out_{i}_en_spare_pend_1_level (access R/W1TC)
  [18] ENABLE_LEVEL_VPAC_OUT_{i}_EN_SPARE_PEND_1_PULSE_CLR — Enable Clear for level_vpac_out_{i}_en_spare_pend_1_pulse (access R/W1TC)
  [17] ENABLE_LEVEL_VPAC_OUT_{i}_EN_SPARE_PEND_0_LEVEL_CLR — Enable Clear for level_vpac_out_{i}_en_spare_pend_0_level (access R/W1TC)
  [16] ENABLE_LEVEL_VPAC_OUT_{i}_EN_SPARE_PEND_0_PULSE_CLR — Enable Clear for level_vpac_out_{i}_en_spare_pend_0_pulse (access R/W1TC)
  [15] ENABLE_LEVEL_VPAC_OUT_{i}_EN_SPARE_DEC_1_CLR — Enable Clear for level_vpac_out_{i}_en_spare_dec_1 (access R/W1TC)
  [14] ENABLE_LEVEL_VPAC_OUT_{i}_EN_SPARE_DEC_0_CLR — Enable Clear for level_vpac_out_{i}_en_spare_dec_0 (access R/W1TC)
  [13] ENABLE_LEVEL_VPAC_OUT_{i}_EN_TDONE_6_CLR — Enable Clear for level_vpac_out_{i}_en_tdone_6 (access R/W1TC)
  [12] ENABLE_LEVEL_VPAC_OUT_{i}_EN_TDONE_5_CLR — Enable Clear for level_vpac_out_{i}_en_tdone_5 (access R/W1TC)
  [11] ENABLE_LEVEL_VPAC_OUT_{i}_EN_TDONE_4_CLR — Enable Clear for level_vpac_out_{i}_en_tdone_4 (access R/W1TC)
  [9] ENABLE_LEVEL_VPAC_OUT_{i}_EN_TDONE_2_CLR — Enable Clear for level_vpac_out_{i}_en_tdone_2 (access R/W1TC)
  [7] ENABLE_LEVEL_VPAC_OUT_{i}_EN_TDONE_0_CLR — Enable Clear for level_vpac_out_{i}_en_tdone_0 (access R/W1TC)
  [n] ENABLE_LEVEL_VPAC_OUT_{i}_EN_PIPE_DONE_{n}_CLR (n=0..6) — Enable Clear for level_vpac_out_{i}_en_pipe_done_{n} (access R/W1TC)
{0x310+0x20*i} CP_INTD__INTD_CFG__INTD_CFG_enable_clr_reg_level_vpac_out_{i}_4 (i=0..5) — Enable Clear Register {8i+4}
  [n] ENABLE_LEVEL_VPAC_OUT_{i}_EN_UTC0_COMPLETE_{n}_CLR (n=0..31) — Enable Clear for level_vpac_out_{i}_en_utc0_complete_{n} (access R/W1TC)
{0x314+0x20*i} CP_INTD__INTD_CFG__INTD_CFG_enable_clr_reg_level_vpac_out_{i}_5 (i=0..5) — Enable Clear Register {8i+5}
  [n] ENABLE_LEVEL_VPAC_OUT_{i}_EN_UTC1_COMPLETE_{n}_CLR (n=0..31) — Enable Clear for level_vpac_out_{i}_en_utc1_complete_{n} (access R/W1TC)
{0x318+0x20*i} CP_INTD__INTD_CFG__INTD_CFG_enable_clr_reg_level_vpac_out_{i}_6 (i=0..5) — Enable Clear Register {8i+6}
  [n-32] ENABLE_LEVEL_VPAC_OUT_{i}_EN_UTC1_COMPLETE_{n}_CLR (n=32..63) — Enable Clear for level_vpac_out_{i}_en_utc1_complete_{n} (access R/W1TC)
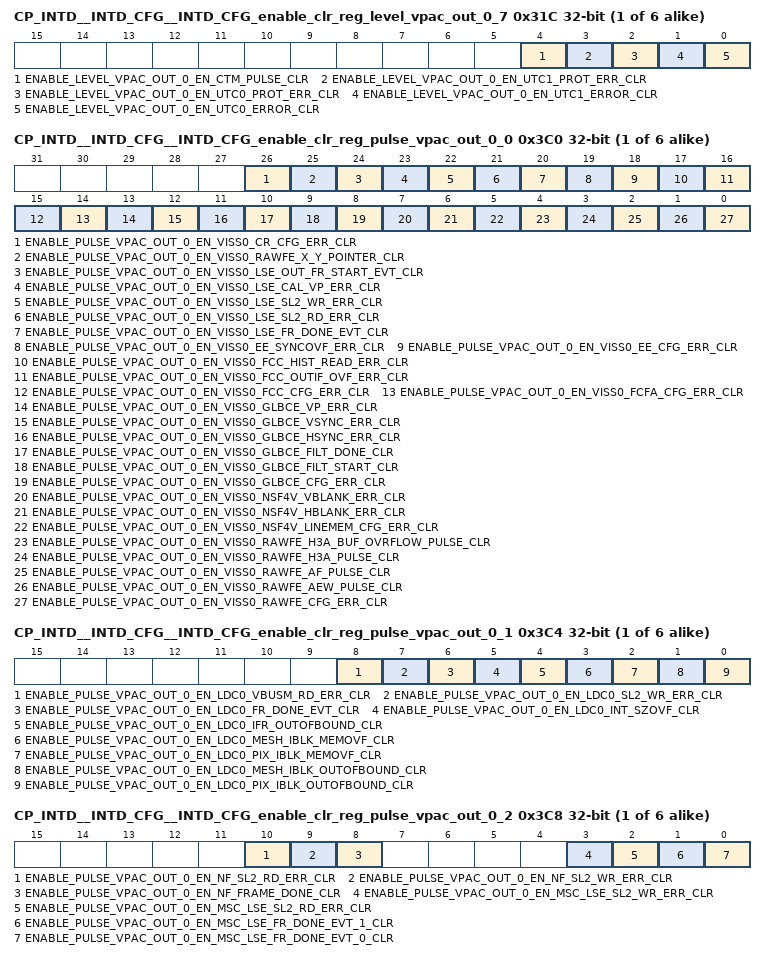
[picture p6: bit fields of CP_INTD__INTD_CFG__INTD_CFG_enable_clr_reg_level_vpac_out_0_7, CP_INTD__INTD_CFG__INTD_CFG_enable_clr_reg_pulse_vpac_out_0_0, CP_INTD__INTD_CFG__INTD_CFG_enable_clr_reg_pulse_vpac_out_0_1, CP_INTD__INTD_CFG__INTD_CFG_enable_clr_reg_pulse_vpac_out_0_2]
{0x31C+0x20*i} CP_INTD__INTD_CFG__INTD_CFG_enable_clr_reg_level_vpac_out_{i}_7 (i=0..5) — Enable Clear Register {8i+7}
  [4] ENABLE_LEVEL_VPAC_OUT_{i}_EN_CTM_PULSE_CLR — Enable Clear for level_vpac_out_{i}_en_ctm_pulse (access R/W1TC)
  [3] ENABLE_LEVEL_VPAC_OUT_{i}_EN_UTC1_PROT_ERR_CLR — Enable Clear for level_vpac_out_{i}_en_utc1_prot_err (access R/W1TC)
  [2] ENABLE_LEVEL_VPAC_OUT_{i}_EN_UTC0_PROT_ERR_CLR — Enable Clear for level_vpac_out_{i}_en_utc0_prot_err (access R/W1TC)
  [1] ENABLE_LEVEL_VPAC_OUT_{i}_EN_UTC1_ERROR_CLR — Enable Clear for level_vpac_out_{i}_en_utc1_error (access R/W1TC)
  [0] ENABLE_LEVEL_VPAC_OUT_{i}_EN_UTC0_ERROR_CLR — Enable Clear for level_vpac_out_{i}_en_utc0_error (access R/W1TC)
{0x3C0+0x20*i} CP_INTD__INTD_CFG__INTD_CFG_enable_clr_reg_pulse_vpac_out_{i}_0 (i=0..5) — Enable Clear Register {8i+48}
  [26] ENABLE_PULSE_VPAC_OUT_{i}_EN_VISS0_CR_CFG_ERR_CLR — Enable Clear for pulse_vpac_out_{i}_en_viss0_cr_cfg_err (access R/W1TC)
  [25] ENABLE_PULSE_VPAC_OUT_{i}_EN_VISS0_RAWFE_X_Y_POINTER_CLR — Enable Clear for pulse_vpac_out_{i}_en_viss0_rawfe_x_y_pointer (access R/W1TC)
  [24] ENABLE_PULSE_VPAC_OUT_{i}_EN_VISS0_LSE_OUT_FR_START_EVT_CLR — Enable Clear for pulse_vpac_out_{i}_en_viss0_lse_out_fr_start_evt (access R/W1TC)
  [23] ENABLE_PULSE_VPAC_OUT_{i}_EN_VISS0_LSE_CAL_VP_ERR_CLR — Enable Clear for pulse_vpac_out_{i}_en_viss0_lse_cal_vp_err (access R/W1TC)
  [22] ENABLE_PULSE_VPAC_OUT_{i}_EN_VISS0_LSE_SL2_WR_ERR_CLR — Enable Clear for pulse_vpac_out_{i}_en_viss0_lse_sl2_wr_err (access R/W1TC)
  [21] ENABLE_PULSE_VPAC_OUT_{i}_EN_VISS0_LSE_SL2_RD_ERR_CLR — Enable Clear for pulse_vpac_out_{i}_en_viss0_lse_sl2_rd_err (access R/W1TC)
  [20] ENABLE_PULSE_VPAC_OUT_{i}_EN_VISS0_LSE_FR_DONE_EVT_CLR — Enable Clear for pulse_vpac_out_{i}_en_viss0_lse_fr_done_evt (access R/W1TC)
  [19] ENABLE_PULSE_VPAC_OUT_{i}_EN_VISS0_EE_SYNCOVF_ERR_CLR — Enable Clear for pulse_vpac_out_{i}_en_viss0_ee_syncovf_err (access R/W1TC)
  [18] ENABLE_PULSE_VPAC_OUT_{i}_EN_VISS0_EE_CFG_ERR_CLR — Enable Clear for pulse_vpac_out_{i}_en_viss0_ee_cfg_err (access R/W1TC)
  [17] ENABLE_PULSE_VPAC_OUT_{i}_EN_VISS0_FCC_HIST_READ_ERR_CLR — Enable Clear for pulse_vpac_out_{i}_en_viss0_fcc_hist_read_err (access R/W1TC)
  [16] ENABLE_PULSE_VPAC_OUT_{i}_EN_VISS0_FCC_OUTIF_OVF_ERR_CLR — Enable Clear for pulse_vpac_out_{i}_en_viss0_fcc_outif_ovf_err (access R/W1TC)
  [15] ENABLE_PULSE_VPAC_OUT_{i}_EN_VISS0_FCC_CFG_ERR_CLR — Enable Clear for pulse_vpac_out_{i}_en_viss0_fcc_cfg_err (access R/W1TC)
  [14] ENABLE_PULSE_VPAC_OUT_{i}_EN_VISS0_FCFA_CFG_ERR_CLR — Enable Clear for pulse_vpac_out_{i}_en_viss0_fcfa_cfg_err (access R/W1TC)
  [13] ENABLE_PULSE_VPAC_OUT_{i}_EN_VISS0_GLBCE_VP_ERR_CLR — Enable Clear for pulse_vpac_out_{i}_en_viss0_glbce_vp_err (access R/W1TC)
  [12] ENABLE_PULSE_VPAC_OUT_{i}_EN_VISS0_GLBCE_VSYNC_ERR_CLR — Enable Clear for pulse_vpac_out_{i}_en_viss0_glbce_vsync_err (access R/W1TC)
  [11] ENABLE_PULSE_VPAC_OUT_{i}_EN_VISS0_GLBCE_HSYNC_ERR_CLR — Enable Clear for pulse_vpac_out_{i}_en_viss0_glbce_hsync_err (access R/W1TC)
  [10] ENABLE_PULSE_VPAC_OUT_{i}_EN_VISS0_GLBCE_FILT_DONE_CLR — Enable Clear for pulse_vpac_out_{i}_en_viss0_glbce_filt_done (access R/W1TC)
  [9] ENABLE_PULSE_VPAC_OUT_{i}_EN_VISS0_GLBCE_FILT_START_CLR — Enable Clear for pulse_vpac_out_{i}_en_viss0_glbce_filt_start (access R/W1TC)
  [8] ENABLE_PULSE_VPAC_OUT_{i}_EN_VISS0_GLBCE_CFG_ERR_CLR — Enable Clear for pulse_vpac_out_{i}_en_viss0_glbce_cfg_err (access R/W1TC)
  [7] ENABLE_PULSE_VPAC_OUT_{i}_EN_VISS0_NSF4V_VBLANK_ERR_CLR — Enable Clear for pulse_vpac_out_{i}_en_viss0_nsf4v_vblank_err (access R/W1TC)
  [6] ENABLE_PULSE_VPAC_OUT_{i}_EN_VISS0_NSF4V_HBLANK_ERR_CLR — Enable Clear for pulse_vpac_out_{i}_en_viss0_nsf4v_hblank_err (access R/W1TC)
  [5] ENABLE_PULSE_VPAC_OUT_{i}_EN_VISS0_NSF4V_LINEMEM_CFG_ERR_CLR — Enable Clear for pulse_vpac_out_{i}_en_viss0_nsf4v_linemem_cfg_err (access R/W1TC)
  [4] ENABLE_PULSE_VPAC_OUT_{i}_EN_VISS0_RAWFE_H3A_BUF_OVRFLOW_PULSE_CLR — Enable Clear for pulse_vpac_out_{i}_en_viss0_rawfe_h3a_buf_ovrflow_pulse (access R/W1TC)
  [3] ENABLE_PULSE_VPAC_OUT_{i}_EN_VISS0_RAWFE_H3A_PULSE_CLR — Enable Clear for pulse_vpac_out_{i}_en_viss0_rawfe_h3a_pulse (access R/W1TC)
  [2] ENABLE_PULSE_VPAC_OUT_{i}_EN_VISS0_RAWFE_AF_PULSE_CLR — Enable Clear for pulse_vpac_out_{i}_en_viss0_rawfe_af_pulse (access R/W1TC)
  [1] ENABLE_PULSE_VPAC_OUT_{i}_EN_VISS0_RAWFE_AEW_PULSE_CLR — Enable Clear for pulse_vpac_out_{i}_en_viss0_rawfe_aew_pulse (access R/W1TC)
  [0] ENABLE_PULSE_VPAC_OUT_{i}_EN_VISS0_RAWFE_CFG_ERR_CLR — Enable Clear for pulse_vpac_out_{i}_en_viss0_rawfe_cfg_err (access R/W1TC)
{0x3C4+0x20*i} CP_INTD__INTD_CFG__INTD_CFG_enable_clr_reg_pulse_vpac_out_{i}_1 (i=0..5) — Enable Clear Register {8i+49}
  [8] ENABLE_PULSE_VPAC_OUT_{i}_EN_LDC0_VBUSM_RD_ERR_CLR — Enable Clear for pulse_vpac_out_{i}_en_ldc0_vbusm_rd_err (access R/W1TC)
  [7] ENABLE_PULSE_VPAC_OUT_{i}_EN_LDC0_SL2_WR_ERR_CLR — Enable Clear for pulse_vpac_out_{i}_en_ldc0_sl2_wr_err (access R/W1TC)
  [6] ENABLE_PULSE_VPAC_OUT_{i}_EN_LDC0_FR_DONE_EVT_CLR — Enable Clear for pulse_vpac_out_{i}_en_ldc0_fr_done_evt (access R/W1TC)
  [5] ENABLE_PULSE_VPAC_OUT_{i}_EN_LDC0_INT_SZOVF_CLR — Enable Clear for pulse_vpac_out_{i}_en_ldc0_int_szovf (access R/W1TC)
  [4] ENABLE_PULSE_VPAC_OUT_{i}_EN_LDC0_IFR_OUTOFBOUND_CLR — Enable Clear for pulse_vpac_out_{i}_en_ldc0_ifr_outofbound (access R/W1TC)
  [3] ENABLE_PULSE_VPAC_OUT_{i}_EN_LDC0_MESH_IBLK_MEMOVF_CLR — Enable Clear for pulse_vpac_out_{i}_en_ldc0_mesh_iblk_memovf (access R/W1TC)
  [2] ENABLE_PULSE_VPAC_OUT_{i}_EN_LDC0_PIX_IBLK_MEMOVF_CLR — Enable Clear for pulse_vpac_out_{i}_en_ldc0_pix_iblk_memovf (access R/W1TC)
  [1] ENABLE_PULSE_VPAC_OUT_{i}_EN_LDC0_MESH_IBLK_OUTOFBOUND_CLR — Enable Clear for pulse_vpac_out_{i}_en_ldc0_mesh_iblk_outofbound (access R/W1TC)
  [0] ENABLE_PULSE_VPAC_OUT_{i}_EN_LDC0_PIX_IBLK_OUTOFBOUND_CLR — Enable Clear for pulse_vpac_out_{i}_en_ldc0_pix_iblk_outofbound (access R/W1TC)
{0x3C8+0x20*i} CP_INTD__INTD_CFG__INTD_CFG_enable_clr_reg_pulse_vpac_out_{i}_2 (i=0..5) — Enable Clear Register {8i+50}
  [10] ENABLE_PULSE_VPAC_OUT_{i}_EN_NF_SL2_RD_ERR_CLR — Enable Clear for pulse_vpac_out_{i}_en_nf_sl2_rd_err (access R/W1TC)
  [9] ENABLE_PULSE_VPAC_OUT_{i}_EN_NF_SL2_WR_ERR_CLR — Enable Clear for pulse_vpac_out_{i}_en_nf_sl2_wr_err (access R/W1TC)
  [8] ENABLE_PULSE_VPAC_OUT_{i}_EN_NF_FRAME_DONE_CLR — Enable Clear for pulse_vpac_out_{i}_en_nf_frame_done (access R/W1TC)
  [3] ENABLE_PULSE_VPAC_OUT_{i}_EN_MSC_LSE_SL2_WR_ERR_CLR — Enable Clear for pulse_vpac_out_{i}_en_msc_lse_sl2_wr_err (access R/W1TC)
  [2] ENABLE_PULSE_VPAC_OUT_{i}_EN_MSC_LSE_SL2_RD_ERR_CLR — Enable Clear for pulse_vpac_out_{i}_en_msc_lse_sl2_rd_err (access R/W1TC)
  [1] ENABLE_PULSE_VPAC_OUT_{i}_EN_MSC_LSE_FR_DONE_EVT_1_CLR — Enable Clear for pulse_vpac_out_{i}_en_msc_lse_fr_done_evt_1 (access R/W1TC)
  [0] ENABLE_PULSE_VPAC_OUT_{i}_EN_MSC_LSE_FR_DONE_EVT_0_CLR — Enable Clear for pulse_vpac_out_{i}_en_msc_lse_fr_done_evt_0 (access R/W1TC)
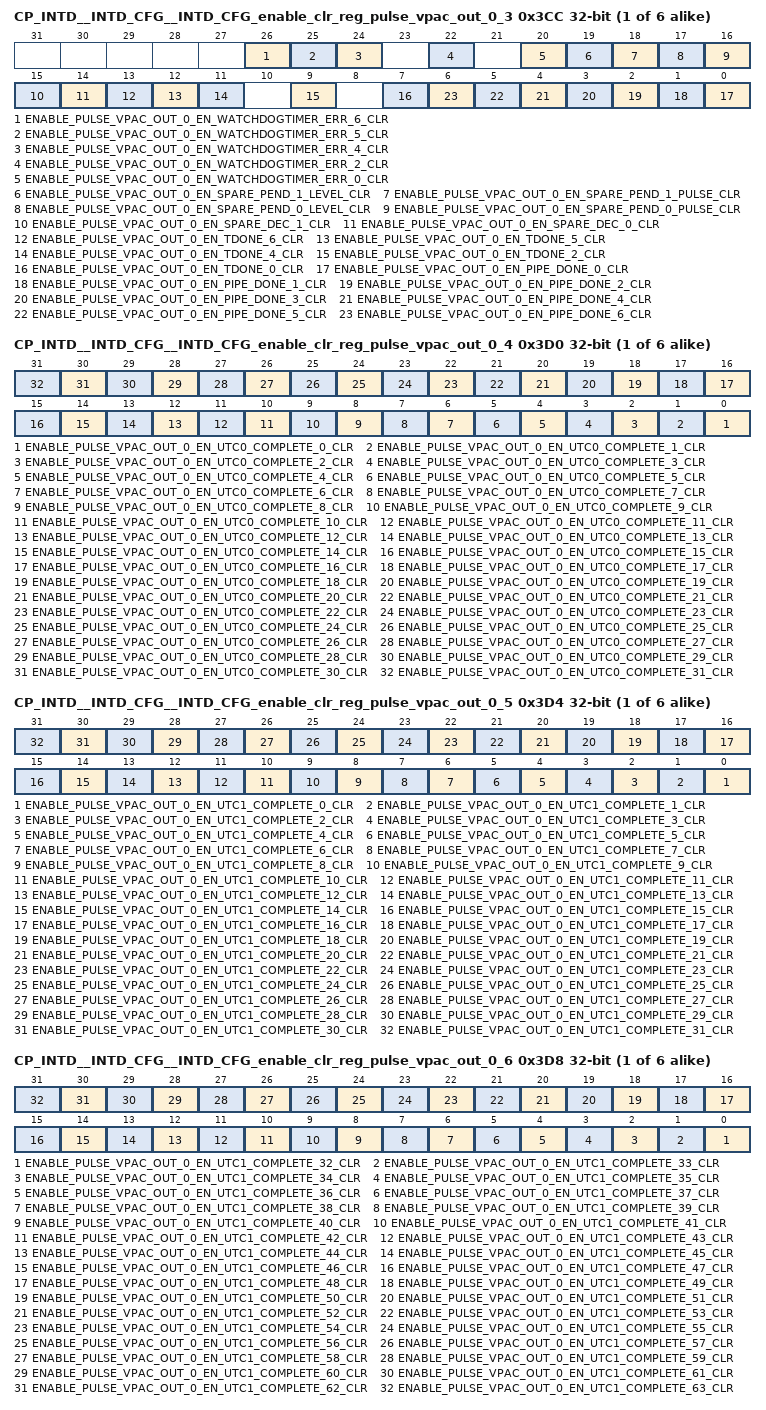
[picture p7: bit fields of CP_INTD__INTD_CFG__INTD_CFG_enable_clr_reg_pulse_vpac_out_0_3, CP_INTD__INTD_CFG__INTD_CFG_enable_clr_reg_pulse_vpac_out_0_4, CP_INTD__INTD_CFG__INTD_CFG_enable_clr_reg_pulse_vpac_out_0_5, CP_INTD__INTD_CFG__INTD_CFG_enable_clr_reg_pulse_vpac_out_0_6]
{0x3CC+0x20*i} CP_INTD__INTD_CFG__INTD_CFG_enable_clr_reg_pulse_vpac_out_{i}_3 (i=0..5) — Enable Clear Register {8i+51}
  [26] ENABLE_PULSE_VPAC_OUT_{i}_EN_WATCHDOGTIMER_ERR_6_CLR — Enable Clear for pulse_vpac_out_{i}_en_watchdogtimer_err_6 (access R/W1TC)
  [25] ENABLE_PULSE_VPAC_OUT_{i}_EN_WATCHDOGTIMER_ERR_5_CLR — Enable Clear for pulse_vpac_out_{i}_en_watchdogtimer_err_5 (access R/W1TC)
  [24] ENABLE_PULSE_VPAC_OUT_{i}_EN_WATCHDOGTIMER_ERR_4_CLR — Enable Clear for pulse_vpac_out_{i}_en_watchdogtimer_err_4 (access R/W1TC)
  [22] ENABLE_PULSE_VPAC_OUT_{i}_EN_WATCHDOGTIMER_ERR_2_CLR — Enable Clear for pulse_vpac_out_{i}_en_watchdogtimer_err_2 (access R/W1TC)
  [20] ENABLE_PULSE_VPAC_OUT_{i}_EN_WATCHDOGTIMER_ERR_0_CLR — Enable Clear for pulse_vpac_out_{i}_en_watchdogtimer_err_0 (access R/W1TC)
  [19] ENABLE_PULSE_VPAC_OUT_{i}_EN_SPARE_PEND_1_LEVEL_CLR — Enable Clear for pulse_vpac_out_{i}_en_spare_pend_1_level (access R/W1TC)
  [18] ENABLE_PULSE_VPAC_OUT_{i}_EN_SPARE_PEND_1_PULSE_CLR — Enable Clear for pulse_vpac_out_{i}_en_spare_pend_1_pulse (access R/W1TC)
  [17] ENABLE_PULSE_VPAC_OUT_{i}_EN_SPARE_PEND_0_LEVEL_CLR — Enable Clear for pulse_vpac_out_{i}_en_spare_pend_0_level (access R/W1TC)
  [16] ENABLE_PULSE_VPAC_OUT_{i}_EN_SPARE_PEND_0_PULSE_CLR — Enable Clear for pulse_vpac_out_{i}_en_spare_pend_0_pulse (access R/W1TC)
  [15] ENABLE_PULSE_VPAC_OUT_{i}_EN_SPARE_DEC_1_CLR — Enable Clear for pulse_vpac_out_{i}_en_spare_dec_1 (access R/W1TC)
  [14] ENABLE_PULSE_VPAC_OUT_{i}_EN_SPARE_DEC_0_CLR — Enable Clear for pulse_vpac_out_{i}_en_spare_dec_0 (access R/W1TC)
  [13] ENABLE_PULSE_VPAC_OUT_{i}_EN_TDONE_6_CLR — Enable Clear for pulse_vpac_out_{i}_en_tdone_6 (access R/W1TC)
  [12] ENABLE_PULSE_VPAC_OUT_{i}_EN_TDONE_5_CLR — Enable Clear for pulse_vpac_out_{i}_en_tdone_5 (access R/W1TC)
  [11] ENABLE_PULSE_VPAC_OUT_{i}_EN_TDONE_4_CLR — Enable Clear for pulse_vpac_out_{i}_en_tdone_4 (access R/W1TC)
  [9] ENABLE_PULSE_VPAC_OUT_{i}_EN_TDONE_2_CLR — Enable Clear for pulse_vpac_out_{i}_en_tdone_2 (access R/W1TC)
  [7] ENABLE_PULSE_VPAC_OUT_{i}_EN_TDONE_0_CLR — Enable Clear for pulse_vpac_out_{i}_en_tdone_0 (access R/W1TC)
  [n] ENABLE_PULSE_VPAC_OUT_{i}_EN_PIPE_DONE_{n}_CLR (n=0..6) — Enable Clear for pulse_vpac_out_{i}_en_pipe_done_{n} (access R/W1TC)
{0x3D0+0x20*i} CP_INTD__INTD_CFG__INTD_CFG_enable_clr_reg_pulse_vpac_out_{i}_4 (i=0..5) — Enable Clear Register {8i+52}
  [n] ENABLE_PULSE_VPAC_OUT_{i}_EN_UTC0_COMPLETE_{n}_CLR (n=0..31) — Enable Clear for pulse_vpac_out_{i}_en_utc0_complete_{n} (access R/W1TC)
{0x3D4+0x20*i} CP_INTD__INTD_CFG__INTD_CFG_enable_clr_reg_pulse_vpac_out_{i}_5 (i=0..5) — Enable Clear Register {8i+53}
  [n] ENABLE_PULSE_VPAC_OUT_{i}_EN_UTC1_COMPLETE_{n}_CLR (n=0..31) — Enable Clear for pulse_vpac_out_{i}_en_utc1_complete_{n} (access R/W1TC)
{0x3D8+0x20*i} CP_INTD__INTD_CFG__INTD_CFG_enable_clr_reg_pulse_vpac_out_{i}_6 (i=0..5) — Enable Clear Register {8i+54}
  [n-32] ENABLE_PULSE_VPAC_OUT_{i}_EN_UTC1_COMPLETE_{n}_CLR (n=32..63) — Enable Clear for pulse_vpac_out_{i}_en_utc1_complete_{n} (access R/W1TC)
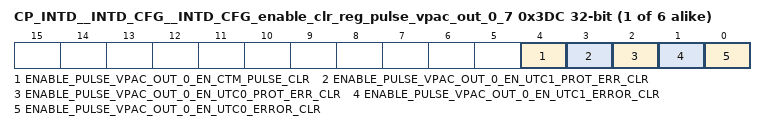
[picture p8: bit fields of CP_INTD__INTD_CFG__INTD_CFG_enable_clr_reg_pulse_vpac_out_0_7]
{0x3DC+0x20*i} CP_INTD__INTD_CFG__INTD_CFG_enable_clr_reg_pulse_vpac_out_{i}_7 (i=0..5) — Enable Clear Register {8i+55}
  [4] ENABLE_PULSE_VPAC_OUT_{i}_EN_CTM_PULSE_CLR — Enable Clear for pulse_vpac_out_{i}_en_ctm_pulse (access R/W1TC)
  [3] ENABLE_PULSE_VPAC_OUT_{i}_EN_UTC1_PROT_ERR_CLR — Enable Clear for pulse_vpac_out_{i}_en_utc1_prot_err (access R/W1TC)
  [2] ENABLE_PULSE_VPAC_OUT_{i}_EN_UTC0_PROT_ERR_CLR — Enable Clear for pulse_vpac_out_{i}_en_utc0_prot_err (access R/W1TC)
  [1] ENABLE_PULSE_VPAC_OUT_{i}_EN_UTC1_ERROR_CLR — Enable Clear for pulse_vpac_out_{i}_en_utc1_error (access R/W1TC)
  [0] ENABLE_PULSE_VPAC_OUT_{i}_EN_UTC0_ERROR_CLR — Enable Clear for pulse_vpac_out_{i}_en_utc0_error (access R/W1TC)
